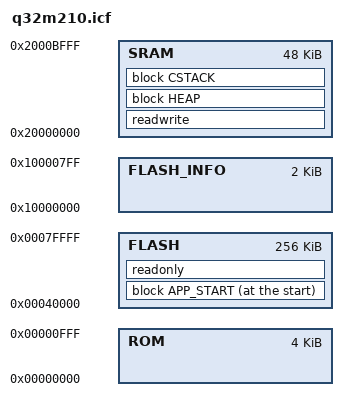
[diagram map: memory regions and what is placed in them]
//-----------------------------------------------------------------------------
// Copyright (c) 2012 Semiconductor Components Industries, LLC
// (d/b/a ON Semiconductor). All Rights Reserved.
//
// This code is the property of ON Semiconductor and may not be redistributed
// in any form without prior written permission from ON Semiconductor. The
// terms of use and warranty for this code are covered by contractual
// agreements between ON Semiconductor and the licensee.
//-----------------------------------------------------------------------------
// q32m210.icf
// - Linker config file for Q32M210 sample code applications
//-----------------------------------------------------------------------------
// $Revision: 1.3 $
// $Date: 2012/04/26 18:50:01 $
//-----------------------------------------------------------------------------

//-----------------------------------------------------------------------------
// Memory Definitions
//-----------------------------------------------------------------------------

// Define a memory region that covers the entire 4 GB addressable space of the
// processor.
define memory mem with size = 4G;

// Define a region for the Program ROM
define region ROM = mem:[from 0x00000000 to 0x00000fff];

// Define a region for the on-chip flash.
define region FLASH = mem:[from 0x00040000 to 0x007ffff];

// Define a region for the read-only info page in flash.
define region FLASH_INFO = mem:[from 0x10000000 to 0x100007ff];

// Define a region for the on-chip SRAM.
define region SRAM = mem:[from 0x20000000 to 0x2000bfff];

//-----------------------------------------------------------------------------
// Application Layout
//-----------------------------------------------------------------------------

// Define a block for the heap.  The size should be set to something other
// than zero if things in the C library that require the heap are used.
define block HEAP with alignment = 8, size = 0x00000000 { };

// Define a block for the stack.  Default to 2K.  If it's too large, memory
// will be wasted.  If it's too small, applications may overflow the stack, in
// which case the application will probably fail.
define block CSTACK with alignment = 8, size = 2K { };

// Define application start block for interrupt vectors, checksum and
// startup function. This layout is expected by the Q32M210 BootROM.
// The STARTUP block assumes that the C runtime library is being used, as
// it references the cmain.o object file
keep { section .checksum };
define block INTVEC { readonly section .intvec };
define block CHECKSUM { readonly section .checksum };
define block STARTUP with alignment = 4 { readonly section .startup };
define block APP_START { first block INTVEC, block CHECKSUM, last block STARTUP };

// Indicate that the read/write values should be initialized by copying from
// flash.
initialize by copy { readwrite };

// Indicate that the values in the .noinit section should not be initialized.
// This includes the stack.
do not initialize { section .noinit };

// Place the application image start block at the start of flash.
place at start of FLASH { block APP_START };

// Place the remainder of the read-only items into flash.
place in FLASH { readonly };

// Place all read/write items into SRAM.
place in SRAM { readwrite, block HEAP, block CSTACK };
